# HC32F558 register map
File version: 1.0
CPU: CM4 r0p1, little endian, MPU, FPU, 4 interrupt priority bits
Registers are 32-bit, read-write, reset 0x0 unless marked. A register's access mark holds for its fields unless they carry their own. Offsets are from the block's base; lines under a group give offsets from that group; [hi:lo] are bit positions; {n}, {i} and the like mark numbered series; 'fields as' and 'values as' point back to an identical list; <NAME> marks a mode.

## Memory map
0x0300E000 ICG size 0x6C
0x40008400 HASH size 0x80
0x40008C00 CRC size 0x100
0x4000E000 SKE size 0x1D0
0x40010400 EFM size 0x3D4
0x40010800 AOS size 0x174
0x40018000 TMR61 size 0x1A0 — desc TMR6
0x40018300 TMR6_COMMON size 0x100
0x40018400 TMR62 size 0x1A0 — desc TMR6
0x40018800 TMR63 size 0x1A0 — desc TMR6
0x40018C00 TMR64 size 0x1A0 — desc TMR6
0x40019000 TMR65 size 0x1A0 — desc TMR6
0x40019400 TMR66 size 0x1A0 — desc TMR6
0x4001C000 SPI1 size 0x1C — desc SPI
0x4001C400 SPI2 size 0x1C — desc SPI
0x4001C800 SPI3 size 0x1C — desc SPI
0x4001CC00 USART1 size 0x20 — desc USART
0x4001D000 USART2 size 0x20 — desc USART
0x4001D400 USART3 size 0x20 — desc USART
0x4001D800 USART4 size 0x20 — desc USART
0x40020C00 DSOGI_PLL size 0xF0
0x40021000 XBAR size 0xC8
0x40024000 TMR01 size 0x18
0x40024400 TMR02 size 0x18
0x4002B000 MCAN1 size 0xFC — desc MCAN
0x4002B400 MCAN2 size 0xFC — desc MCAN
0x4002B800 MCAN3 size 0xFC — desc MCAN
0x4002D800 MCANRAM size 0x18
{0x40033C00+0x400*n} HRPWM{n} size 0x20C (n=1..8) — desc HRPWM
{0x400363C0+0x40*n} HRPWM_EMB{n} size 0x2C (n=1..8) — desc HRPWM_EMB
0x40036800 HRPWM_COMMON size 0x14C
0x40038800 EMB0 size 0x3C — desc EMB
0x40038840 EMB1 size 0x3C — desc EMB
0x40038880 EMB2 size 0x3C — desc EMB
0x400388C0 EMB3 size 0x3C — desc EMB
0x40038900 EMB4 size 0x3C — desc EMB
0x40038940 EMB5 size 0x3C — desc EMB
0x4003A400 TRLPWM1 size 0x400 — desc TRLPWM
0x4003A800 SDFM size 0x2D8
0x4003AC00 TRLPWM2 size 0x400 — desc TRLPWM
{0x4003AF00+0x100*n} CMP{n} size 0x20 (n=1..8)
0x40040000 ADC1 size 0x1B4
0x40040400 ADC2 size 0x1B4
0x40040800 ADC3 size 0x1B4
0x40040C00 ADC4 size 0x180
0x40041000 DAC1 size 0x5C — desc DAC
0x40041400 DAC2 size 0x5C — desc DAC
0x40041800 DAC3 size 0x5C — desc DAC
0x40041C00 DAC4 size 0x5C — desc DAC
0x40042000 TRNG size 0x14
0x40048000 CMU size 0xC104
0x40048000 PWC size 0xC400
0x40048400 FCM1 size 0x24 — desc FCM
0x40048400 FCM_COM size 0x20
0x40048440 FCM2 size 0x24 — desc FCM
0x40048480 FCM3 size 0x24 — desc FCM
0x400484C0 FCM4 size 0x24 — desc FCM
0x40048800 ERMU size 0x604
0x40049000 WDT size 0xC
0x40049400 SWDT size 0xC
0x40049C00 CTC size 0xC
0x4004A800 OTS size 0x10
0x4004CC00 RMU size 0x100
0x4004E000 I2C1 size 0x3C — desc I2C
0x4004E400 I2C2 size 0x3C — desc I2C
0x4004E800 I2C3 size 0x3C — desc I2C
0x4004F800 VREF size 0x204
0x4004FC00 PLA size 0xD0
0x40050000 MPU size 0x70
0x40050800 SRAMC size 0x60
0x40051000 INTC size 0x2AC
0x40053000 DMA1 size 0x238 — desc DMA
0x40053400 DMA2 size 0x238 — desc DMA
0x40053800 GPIO size 0x5AC
0x40055000 CORDIC size 0x1C
0x40055400 PERIC size 0x48
0x40057000 PID1 size 0xFC — desc PID
0x40057100 PID2 size 0xFC — desc PID
0x40057400 PID_CMP size 0x2C
0x40058000 FMAC size 0x218
0x40058800 FMAC_ECC size 0x38
0xE0042000 DBGC size 0x28

## Interrupts
{n+106} CMP{n} (n=1..8) — CMP{n} interrupt
115 SPI_1 (SPI1) — SPI unit 1 interrupt
116 SPI_2 (SPI2) — SPI unit 2 interrupt
117 SPI_3 (SPI3) — SPI unit 3 interrupt

## ADC1
Base 0x40040000
0x00 STR 8-bit
  [0] STRT
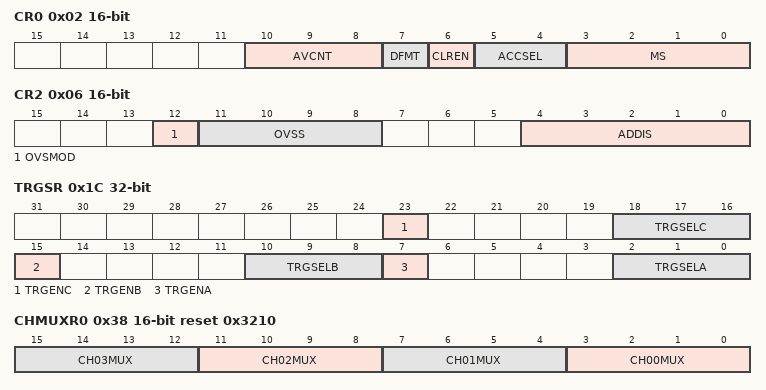
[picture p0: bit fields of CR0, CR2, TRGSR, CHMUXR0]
0x02 CR0 16-bit
  [10:8] AVCNT, [7] DFMT, [6] CLREN, [5:4] ACCSEL, [3:0] MS
0x04 CR1 16-bit
  [2] RSCHSEL
0x06 CR2 16-bit
  [12] OVSMOD, [11:8] OVSS, [4:0] ADDIS
0x0C CHSELRA
  [29:0] CHSELA
0x10 CHSELRB
  [29:0] CHSELB
0x10 CHSELRC (alternate view of CHSELRB)
  [29:0] CHSELC
0x14 AVCHSELR
  [29:0] AVCHSEL
0x18 EXCHSELR 16-bit
  [0] EXCHSEL
0x1C TRGSR
  [23] TRGENC, [18:16] TRGSELC, [15] TRGENB, [10:8] TRGSELB, [7] TRGENA, [2:0] TRGSELA
{0x20+i} SSTR{i} 8-bit reset 0xB (i=0..15)
0x30 SSTRL 8-bit reset 0xB
0x38 CHMUXR0 16-bit reset 0x3210
  [4n+3:4n] CH{n:02}MUX (n=0..3)
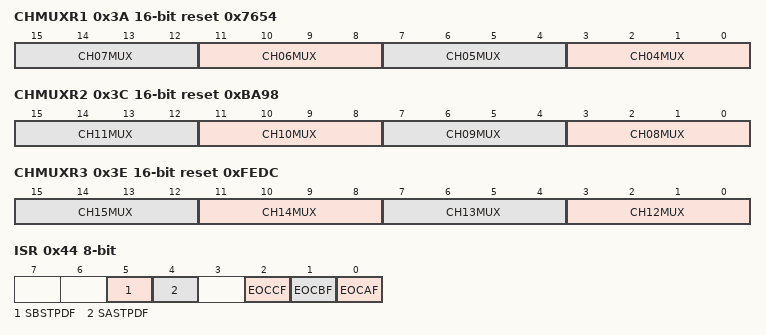
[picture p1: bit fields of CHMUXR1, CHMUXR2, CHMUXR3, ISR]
0x3A CHMUXR1 16-bit reset 0x7654
  [4n-13:4n-16] CH{n:02}MUX (n=4..7)
0x3C CHMUXR2 16-bit reset 0xBA98
  [4n-29:4n-32] CH{n:02}MUX (n=8..11)
0x3E CHMUXR3 16-bit reset 0xFEDC
  [4n-45:4n-48] CH{n}MUX (n=12..15)
0x44 ISR 8-bit ro
  [5] SBSTPDF, [4] SASTPDF, [2] EOCCF, [1] EOCBF, [0] EOCAF
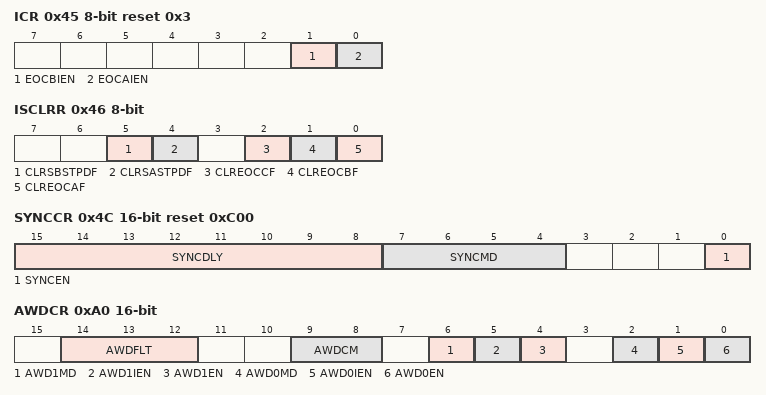
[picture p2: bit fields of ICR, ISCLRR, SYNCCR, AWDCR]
0x45 ICR 8-bit reset 0x3
  [1] EOCBIEN, [0] EOCAIEN
0x46 ISCLRR 8-bit
  [5] CLRSBSTPDF, [4] CLRSASTPDF, [2] CLREOCCF, [1] CLREOCBF, [0] CLREOCAF
0x4C SYNCCR 16-bit reset 0xC00
  [15:8] SYNCDLY, [7:4] SYNCMD, [0] SYNCEN
{0x50+2i} DR{i} 16-bit ro (i=0..29)
0xA0 AWDCR 16-bit
  [14:12] AWDFLT, [9:8] AWDCM, [6] AWD1MD, [5] AWD1IEN, [4] AWD1EN, [2] AWD0MD, [1] AWD0IEN, [0] AWD0EN
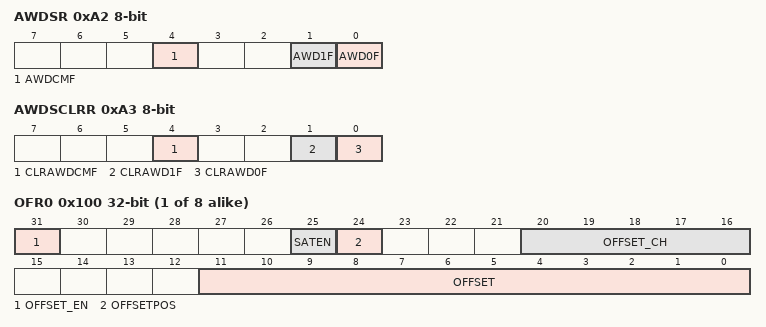
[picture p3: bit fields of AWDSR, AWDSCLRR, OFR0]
0xA2 AWDSR 8-bit ro
  [4] AWDCMF, [1] AWD1F, [0] AWD0F
0xA3 AWDSCLRR 8-bit
  [4] CLRAWDCMF, [1] CLRAWD1F, [0] CLRAWD0F
0xA4 AWD0DR0 16-bit
0xA6 AWD0DR1 16-bit reset 0xFFFF
0xA8 AWD0CHSR 16-bit
  [4:0] AWDCH
0xAC AWD1DR0 16-bit
0xAE AWD1DR1 16-bit reset 0xFFFF
0xB0 AWD1CHSR 16-bit
  [4:0] AWDCH
{0x100+4i} OFR{i} (i=0..7)
  [31] OFFSET_EN, [25] SATEN, [24] OFFSETPOS, [20:16] OFFSET_CH, [11:0] OFFSET
{0x150+4i} FDR{i} ro (i=0..24)

## ADC2
Base 0x40040400
Same registers: ADC3 0x40040800
Registers as ADC1, without SYNCCR, DR28, DR29; these are added or differ:
0x18 EXCHSELR 8-bit
  [0] EXCHSEL

## ADC4
Base 0x40040C00
Registers as ADC2, without SSTR{n} (n=12..15), CHMUXR3, DR{n} (n=12..27), FDR{n} (n=12..24); these are added or differ:
0x0C CHSELRA
  [11:0] CHSELA
0x10 CHSELRB
  [11:0] CHSELB
0x10 CHSELRC (alternate view of CHSELRB)
  [11:0] CHSELC
0x14 AVCHSELR
  [11:0] AVCHSEL
0x34 DIFCHSELR
  [4:0] DIFCHSEL
